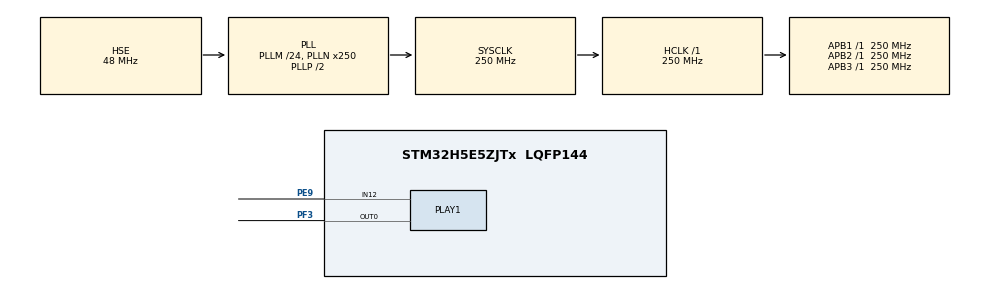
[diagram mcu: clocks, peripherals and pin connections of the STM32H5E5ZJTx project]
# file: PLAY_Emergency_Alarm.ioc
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CORTEX_M33_NS.userName=CORTEX_M33
Mcu.Family=STM32H5
Mcu.Name=STM32H5E5ZJTx
Mcu.Package=LQFP144
NVIC.PLAY1_IRQn=true\:0\:0\:false\:false\:true\:true\:true\:true
NVIC.PriorityGroup=NVIC_PRIORITYGROUP_4
PE9.GPIO_PuPd=GPIO_PULLDOWN
PE9.GPIO_Speed=GPIO_SPEED_FREQ_HIGH
PE9.Mode=PLAY1_IN12
PE9.Signal=PLAY1_IN12
PF3.GPIO_Speed=GPIO_SPEED_FREQ_HIGH
PF3.Mode=PLAY1_OUT0
PF3.Signal=PLAY1_OUT0
PH0-OSC_IN(PH0).Mode=HSE-External-Oscillator
PH0-OSC_IN(PH0).Signal=RCC_OSC_IN
PH1-OSC_OUT(PH1).Mode=HSE-External-Oscillator
PH1-OSC_OUT(PH1).Signal=RCC_OSC_OUT
PLAY1.Channel-PLAY1_IN12=PLAY_CHANNEL_12
PLAY1.InputEdgeDetection12=HAL_PLAY_EDGE_DETECTION_RISING
PLAY1.InputPulseWidth12=0
PLAY1.InputSignal12=HAL_PLAY1_IN_IN12_MUX12
PLAY1.L0ClockEnable=HAL_PLAY_LUT_CLK_GATE_LUT15_OUT_REGISTERED
PLAY1.L0Input0=HAL_PLAY_LUT_INPUT_LUT0_OUT_REGISTERED
PLAY1.L0Input1=HAL_PLAY_LUT_INPUT_SWTRIG0
PLAY1.L0InputType0=OutputRegisteredSignal
PLAY1.L0LUT=0x5555
PLAY1.L10Input0=HAL_PLAY_LUT_INPUT_LUT8_OUT_DIRECT
PLAY1.L10Input1=HAL_PLAY_LUT_INPUT_LUT9_OUT_DIRECT
PLAY1.L10Input2=HAL_PLAY_LUT_INPUT_LUT12_OUT_DIRECT
PLAY1.L10Input3=HAL_PLAY_LUT_INPUT_LUT13_OUT_DIRECT
PLAY1.L10InputType0=OutputDirectSignal
PLAY1.L10InputType1=OutputDirectSignal
PLAY1.L10InputType2=OutputDirectSignal
PLAY1.L10InputType3=OutputDirectSignal
PLAY1.L10LUT=0xFFFE
PLAY1.L11Input0=HAL_PLAY_LUT_INPUT_LUT15_OUT_REGISTERED
PLAY1.L11Input1=HAL_PLAY_LUT_INPUT_LUT10_OUT_DIRECT
PLAY1.L11InputType0=OutputRegisteredSignal
PLAY1.L11InputType1=OutputDirectSignal
PLAY1.L11LUT=0x8888
PLAY1.L12Input0=HAL_PLAY_LUT_INPUT_LUT1_OUT_REGISTERED
PLAY1.L12Input1=HAL_PLAY_LUT_INPUT_LUT2_OUT_REGISTERED
PLAY1.L12Input2=HAL_PLAY_LUT_INPUT_LUT3_OUT_REGISTERED
PLAY1.L12Input3=HAL_PLAY_LUT_INPUT_LUT5_OUT_REGISTERED
PLAY1.L12InputType0=OutputRegisteredSignal
PLAY1.L12InputType1=OutputRegisteredSignal
PLAY1.L12InputType2=OutputRegisteredSignal
PLAY1.L12InputType3=OutputRegisteredSignal
PLAY1.L12LUT=0x0100
PLAY1.L13Input1=HAL_PLAY_LUT_INPUT_LUT1_OUT_REGISTERED
PLAY1.L13Input2=HAL_PLAY_LUT_INPUT_LUT3_OUT_REGISTERED
PLAY1.L13Input3=HAL_PLAY_LUT_INPUT_LUT5_OUT_REGISTERED
PLAY1.L13InputType0=OutputRegisteredSignal
PLAY1.L13InputType1=OutputRegisteredSignal
PLAY1.L13InputType2=OutputRegisteredSignal
PLAY1.L13InputType3=OutputRegisteredSignal
PLAY1.L13LUT=0x0400
PLAY1.L15ClockEnable=HAL_PLAY_LUT_CLK_GATE_FILTER12
PLAY1.L15Input0=HAL_PLAY_LUT_INPUT_LUT15_OUT_REGISTERED
PLAY1.L15InputType0=OutputRegisteredSignal
PLAY1.L15LUT=0x5555
PLAY1.L1ClockEnable=HAL_PLAY_LUT_CLK_GATE_LUT15_OUT_REGISTERED
PLAY1.L1Input0=HAL_PLAY_LUT_INPUT_LUT1_OUT_REGISTERED
PLAY1.L1InputType0=OutputRegisteredSignal
PLAY1.L1InputType1=OutputRegisteredSignal
PLAY1.L1LUT=0x6666
PLAY1.L2ClockEnable=HAL_PLAY_LUT_CLK_GATE_LUT15_OUT_REGISTERED
PLAY1.L2Input0=HAL_PLAY_LUT_INPUT_LUT2_OUT_REGISTERED
PLAY1.L2Input1=HAL_PLAY_LUT_INPUT_LUT1_OUT_REGISTERED
PLAY1.L2InputType0=OutputRegisteredSignal
PLAY1.L2InputType1=OutputRegisteredSignal
PLAY1.L2InputType2=OutputRegisteredSignal
PLAY1.L2LUT=0x6A6A
PLAY1.L3ClockEnable=HAL_PLAY_LUT_CLK_GATE_LUT15_OUT_REGISTERED
PLAY1.L3Input0=HAL_PLAY_LUT_INPUT_LUT3_OUT_REGISTERED
PLAY1.L3Input1=HAL_PLAY_LUT_INPUT_LUT2_OUT_REGISTERED
PLAY1.L3Input2=HAL_PLAY_LUT_INPUT_LUT1_OUT_REGISTERED
PLAY1.L3InputType0=OutputRegisteredSignal
PLAY1.L3InputType1=OutputRegisteredSignal
PLAY1.L3InputType2=OutputRegisteredSignal
PLAY1.L3InputType3=OutputRegisteredSignal
PLAY1.L3LUT=0x6AAA
PLAY1.L4ClockEnable=HAL_PLAY_LUT_CLK_GATE_ON
PLAY1.L4Input0=HAL_PLAY_LUT_INPUT_LUT3_OUT_REGISTERED
PLAY1.L4Input1=HAL_PLAY_LUT_INPUT_LUT2_OUT_REGISTERED
PLAY1.L4Input2=HAL_PLAY_LUT_INPUT_LUT1_OUT_REGISTERED
PLAY1.L4InputType0=OutputRegisteredSignal
PLAY1.L4InputType1=OutputRegisteredSignal
PLAY1.L4InputType2=OutputRegisteredSignal
PLAY1.L4InputType3=OutputRegisteredSignal
PLAY1.L4LUT=0x8000
PLAY1.L5ClockEnable=HAL_PLAY_LUT_CLK_GATE_LUT15_OUT_REGISTERED
PLAY1.L5Input0=HAL_PLAY_LUT_INPUT_LUT5_OUT_REGISTERED
PLAY1.L5Input1=HAL_PLAY_LUT_INPUT_LUT4_OUT_DIRECT
PLAY1.L5InputType0=OutputRegisteredSignal
PLAY1.L5InputType1=OutputDirectSignal
PLAY1.L5LUT=0x6666
PLAY1.L8Input1=HAL_PLAY_LUT_INPUT_LUT2_OUT_REGISTERED
PLAY1.L8Input2=HAL_PLAY_LUT_INPUT_LUT3_OUT_REGISTERED
PLAY1.L8Input3=HAL_PLAY_LUT_INPUT_LUT5_OUT_REGISTERED
PLAY1.L8InputType0=OutputRegisteredSignal
PLAY1.L8InputType1=OutputRegisteredSignal
PLAY1.L8InputType2=OutputRegisteredSignal
PLAY1.L8InputType3=OutputRegisteredSignal
PLAY1.L8LUT=0x1151
PLAY1.L9Input1=HAL_PLAY_LUT_INPUT_LUT1_OUT_REGISTERED
PLAY1.L9Input2=HAL_PLAY_LUT_INPUT_LUT3_OUT_REGISTERED
PLAY1.L9Input3=HAL_PLAY_LUT_INPUT_LUT5_OUT_REGISTERED
PLAY1.L9InputType0=OutputRegisteredSignal
PLAY1.L9InputType1=OutputRegisteredSignal
PLAY1.L9InputType2=OutputRegisteredSignal
PLAY1.L9InputType3=OutputRegisteredSignal
PLAY1.L9LUT=0x0031
PLAY1.LUT0InputUsage0=enable
PLAY1.LUT0InputUsage1=disable
PLAY1.LUT10InputUsage0=enable
PLAY1.LUT10InputUsage1=enable
PLAY1.LUT10InputUsage2=enable
PLAY1.LUT10InputUsage3=enable
PLAY1.LUT11InputUsage0=enable
PLAY1.LUT11InputUsage1=enable
PLAY1.LUT11InputUsage2=disable
PLAY1.LUT11InputUsage3=disable
PLAY1.LUT12InputUsage0=enable
PLAY1.LUT12InputUsage1=enable
PLAY1.LUT12InputUsage2=enable
PLAY1.LUT12InputUsage3=enable
PLAY1.LUT13InputUsage0=enable
PLAY1.LUT13InputUsage1=enable
PLAY1.LUT13InputUsage2=enable
PLAY1.LUT13InputUsage3=enable
PLAY1.LUT15InputUsage0=enable
PLAY1.LUT1InputUsage0=enable
PLAY1.LUT1InputUsage1=enable
PLAY1.LUT2InputUsage0=enable
PLAY1.LUT2InputUsage1=enable
PLAY1.LUT2InputUsage2=enable
PLAY1.LUT3InputUsage0=enable
PLAY1.LUT3InputUsage1=enable
PLAY1.LUT3InputUsage2=enable
PLAY1.LUT3InputUsage3=enable
PLAY1.LUT4InputUsage0=enable
PLAY1.LUT4InputUsage1=enable
PLAY1.LUT4InputUsage2=enable
PLAY1.LUT4InputUsage3=enable
PLAY1.LUT5InputUsage0=enable
PLAY1.LUT5InputUsage1=enable
PLAY1.LUT8InputUsage0=enable
PLAY1.LUT8InputUsage1=enable
PLAY1.LUT8InputUsage2=enable
PLAY1.LUT8InputUsage3=enable
PLAY1.LUT9InputUsage0=enable
PLAY1.LUT9InputUsage1=enable
PLAY1.LUT9InputUsage2=enable
PLAY1.LUT9InputUsage3=enable
PLAY1.OutputSignal0=HAL_PLAY_LUT11_OUT_DIRECT
PLAY1.OutputSignal14=HAL_PLAY_LUT15_OUT_REGISTERED
ProjectManager.HeapSize=0x200
ProjectManager.StackSize=0x400
ProjectManager.TargetToolchain=EWARM V9.20
RCC.ADCFreq_Value=250000000
RCC.AHBFreq_Value=250000000
RCC.APB1Freq_Value=250000000
RCC.APB1TimFreq_Value=250000000
RCC.APB2Freq_Value=250000000
RCC.APB2TimFreq_Value=250000000
RCC.APB3Freq_Value=250000000
RCC.CSI_VALUE=4000000
RCC.CortexFreq_Value=250000000
RCC.EPOD_VALUE=48000000
RCC.HCLKFreq_Value=250000000
RCC.HSE_VALUE=48000000
RCC.HSI48_VALUE=48000000
RCC.HSI_VALUE=64000000
RCC.LSE_VALUE=32768
RCC.LSIRC_VALUE=32000
RCC.PLAY1CLockSelection=RCC_PLAY1CLKSOURCE_LSI
RCC.PLAY1Prescaler=RCC_PLAY1_CLK_DIV_4096
RCC.PLL2M=2
RCC.PLL2N=8
RCC.PLL2Source=RCC_PLL2_SOURCE_HSI
RCC.PLLM=24
RCC.PLLN=250
RCC.PLLSourceVirtual=RCC_PLL1_SOURCE_HSE
RCC.SYSCLKFreq_VALUE=250000000
RCC.SYSCLKSource=RCC_SYSCLKSOURCE_PLLCLK
RCC.USBFreq_Value=258000000
RCC.VCOOutputFreq_Value=500000000
VP_CORTEX_M33_NS_VS_Hclk.Mode=Hclk_Mode
VP_ICACHE_VS_ICACHE.Mode=DefaultMode
VP_PLAY1_VS_PLA.Mode=PLAY_Activate
VP_PWR_VS_LPOM.Mode=PowerOptimisation
VP_PWR_VS_SECSignals.Mode=Security/Privilege
board=custom

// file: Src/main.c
/* USER CODE BEGIN Header */
/**
  ******************************************************************************
  * @file           : main.c
  * @brief          : Main program body
  ******************************************************************************
  * @attention
  *
  * Copyright (c) 2025 STMicroelectronics.
  * All rights reserved.
  *
  * This software is licensed under terms that can be found in the LICENSE file
  * in the root directory of this software component.
  * If no LICENSE file comes with this software, it is provided AS-IS.
  *
  ******************************************************************************
  */
/* USER CODE END Header */
#include "main.h"

#define CONFIGURED_INPUT_NBR   1U
#define CONFIGURED_LUT_NBR     13U
#define CONFIGURED_OUTPUT_NBR  2U

HAL_PLAY_HandleTypeDef hplay1;

/* USER CODE BEGIN PV */
EXTI_HandleTypeDef hexti;
/* USER CODE END PV */

void SystemClock_Config(void);
static void MX_GPIO_Init(void);
static void MX_ICACHE_Init(void);
static void MX_PLAY1_Init(void);

int main(void)
{

  /* USER CODE BEGIN 1 */
  HAL_PLAY_EdgeTriggerConfTypeDef edge_trigger_config;

  /* USER CODE END 1 */

  /* MCU Configuration--------------------------------------------------------*/

  /* Reset of all peripherals, Initializes the Flash interface and the Systick. */
  HAL_Init();

  /* USER CODE BEGIN Init */
  HAL_PWR_EnableBkUpAccess();
  /* USER CODE END Init */

  /* Configure the system clock */
  SystemClock_Config();

  /* Initialize all configured peripherals */
  MX_GPIO_Init();
  MX_ICACHE_Init();
  MX_PLAY1_Init();
  /* USER CODE BEGIN 2 */
  BSP_LED_Init(LED_RED);
  BSP_LED_Init(LED_BLUE);

  /* In this example, edge triggers are not used */
  edge_trigger_config.lut_out_falling_mask = 0U;
  edge_trigger_config.lut_out_rising_mask = 0U;

  /* Start PLAY module */
  if (HAL_PLAY_Start(&hplay1, &edge_trigger_config) != HAL_OK)
  {
    Error_Handler();
  }

  /* USER CODE END 2 */

  /* Infinite loop */
  /* USER CODE BEGIN WHILE */
  while (1)
  {
    /* The system enters STOP mode to demonstrate that the alarm signal is fully handled by the PLAY hardware */

    HAL_SuspendTick();

    /* Clear all related wakeup flags*/
    __HAL_PWR_CLEAR_FLAG(PWR_FLAG_STOPF);

    /** Enter STOP Mode with WaitForevent parameter, a interrupt enabled in NVIC would wake the system up
      * During STOP mode, the PLAY LUT output flags are not functional.
      * To wakeup the system, this example configures the PLAY EXTI output so that the falling edge of LUT 15
      * will trigger the EXTI, waking up the system.
      */
    HAL_PWR_EnterSTOPMode(PWR_MAINREGULATOR_ON, PWR_STOPENTRY_WFE);

    /**
      * The user can change the PLAY1_IN12 (PE9) input signal to trigger the alarm signal.
      * As the PLAY peripheral handles the alarm signal, the application does not need to do anything in this step.
      * When the user changes the input signal a second time, the PLAY peripheral will stop the alarm signal.
      * The alarm stop will trigger an EXTI interrupt, which will wake the system.
      * The application will then turn on the LED to indicate that the alarm has been stopped, wait for one second,
      * and go back again in STOP mode.
      */

    /* Reach this point when the MCU wakes up */
    HAL_ResumeTick();

    /* The PLAY interrupt wakes the device up */
    SystemClock_Config();

    /* The alarm was stopped: rising edge on LUT 15 registered output. Turn on the LED */
    BSP_LED_On(LED_BLUE);

    /* Wait for one second so the LED status can be noticed.*/
    HAL_Delay(1000);
    BSP_LED_Off(LED_BLUE);
    /* USER CODE END WHILE */

  }
}

void SystemClock_Config(void)
{
  RCC_OscInitTypeDef RCC_OscInitStruct = {0};
  RCC_ClkInitTypeDef RCC_ClkInitStruct = {0};

  /** Configure the main internal regulator output voltage
  */
  __HAL_PWR_VOLTAGESCALING_CONFIG(PWR_REGULATOR_VOLTAGE_SCALE0);

  while(!__HAL_PWR_GET_FLAG(PWR_FLAG_VOSRDY)) {}

  /** Initializes the RCC Oscillators according to the specified parameters
  * in the RCC_OscInitTypeDef structure.
  */
  RCC_OscInitStruct.OscillatorType = RCC_OSCILLATORTYPE_LSI|RCC_OSCILLATORTYPE_HSE;
  RCC_OscInitStruct.HSEState = RCC_HSE_ON;
  RCC_OscInitStruct.LSIState = RCC_LSI_ON;
  RCC_OscInitStruct.PLL.PLLState = RCC_PLL_ON;
  RCC_OscInitStruct.PLL.PLLSource = RCC_PLL1_SOURCE_HSE;
  RCC_OscInitStruct.PLL.PLLM = 24;
  RCC_OscInitStruct.PLL.PLLN = 250;
  RCC_OscInitStruct.PLL.PLLP = 2;
  RCC_OscInitStruct.PLL.PLLQ = 2;
  RCC_OscInitStruct.PLL.PLLR = 2;
  RCC_OscInitStruct.PLL.PLLRGE = RCC_PLL1_VCIRANGE_1;
  RCC_OscInitStruct.PLL.PLLVCOSEL = RCC_PLL1_VCORANGE_WIDE;
  RCC_OscInitStruct.PLL.PLLFRACN = 0;
  if (HAL_RCC_OscConfig(&RCC_OscInitStruct) != HAL_OK)
  {
    Error_Handler();
  }

  /** Initializes the CPU, AHB and APB buses clocks
  */
  RCC_ClkInitStruct.ClockType = RCC_CLOCKTYPE_HCLK|RCC_CLOCKTYPE_SYSCLK
                              |RCC_CLOCKTYPE_PCLK1|RCC_CLOCKTYPE_PCLK2
                              |RCC_CLOCKTYPE_PCLK3;
  RCC_ClkInitStruct.SYSCLKSource = RCC_SYSCLKSOURCE_PLLCLK;
  RCC_ClkInitStruct.AHBCLKDivider = RCC_SYSCLK_DIV1;
  RCC_ClkInitStruct.APB1CLKDivider = RCC_HCLK_DIV1;
  RCC_ClkInitStruct.APB2CLKDivider = RCC_HCLK_DIV1;
  RCC_ClkInitStruct.APB3CLKDivider = RCC_HCLK_DIV1;

  if (HAL_RCC_ClockConfig(&RCC_ClkInitStruct, FLASH_LATENCY_5) != HAL_OK)
  {
    Error_Handler();
  }

  /** Configure the programming delay
  */
  __HAL_FLASH_SET_PROGRAM_DELAY(FLASH_PROGRAMMING_DELAY_2);
}

static void MX_ICACHE_Init(void)
{

  /** Enable instruction cache (default 2-ways set associative cache)
  */
  if (HAL_ICACHE_Enable() != HAL_OK)
  {
    Error_Handler();
  }

}

static void MX_PLAY1_Init(void)
{

  HAL_PLAY_IN_ConfTypeDef configINPUTs[CONFIGURED_INPUT_NBR];
  HAL_PLAY_LUT_ConfTypeDef configLUTs[CONFIGURED_LUT_NBR];
  HAL_PLAY_OUT_ConfTypeDef configOUTPUTs[CONFIGURED_OUTPUT_NBR];

  hplay1.instance = PLAY1;

  if (HAL_PLAY_Init(&hplay1) != HAL_OK)
  {
    Error_Handler();
  }

  /** Configure Input 12
  */
  configINPUTs[0].min_pulse_width = 0;
  configINPUTs[0].mode = HAL_PLAY_EDGE_DETECTION_RISING;
  configINPUTs[0].source = HAL_PLAY1_IN_IN12_MUX12;
  if (HAL_PLAY_INPUT_SetConfig(&hplay1, configINPUTs, CONFIGURED_INPUT_NBR) != HAL_OK)
  {
    Error_Handler();
  }

  /** Configure the Logic Element 0
  */
  configLUTs[0].lut = HAL_PLAY_LUT0;
  configLUTs[0].truth_table = 0x5555;
  configLUTs[0].input_source[HAL_PLAY_LUT_INPUT0] = HAL_PLAY_LUT_INPUT_LUT0_OUT_REGISTERED;
  configLUTs[0].input_source[HAL_PLAY_LUT_INPUT1] = HAL_PLAY_LUT_INPUT_SWTRIG0;
  configLUTs[0].input_source[HAL_PLAY_LUT_INPUT2] = HAL_PLAY_LUT_INPUT_DEFAULT;
  configLUTs[0].input_source[HAL_PLAY_LUT_INPUT3] = HAL_PLAY_LUT_INPUT_DEFAULT;
  configLUTs[0].clk_gate_source = HAL_PLAY_LUT_CLK_GATE_LUT15_OUT_REGISTERED;

  /** Configure the Logic Element 1
  */
  configLUTs[1].lut = HAL_PLAY_LUT1;
  configLUTs[1].truth_table = 0x6666;
  configLUTs[1].input_source[HAL_PLAY_LUT_INPUT0] = HAL_PLAY_LUT_INPUT_LUT1_OUT_REGISTERED;
  configLUTs[1].input_source[HAL_PLAY_LUT_INPUT1] = HAL_PLAY_LUT_INPUT_LUT0_OUT_REGISTERED;
  configLUTs[1].input_source[HAL_PLAY_LUT_INPUT2] = HAL_PLAY_LUT_INPUT_DEFAULT;
  configLUTs[1].input_source[HAL_PLAY_LUT_INPUT3] = HAL_PLAY_LUT_INPUT_DEFAULT;
  configLUTs[1].clk_gate_source = HAL_PLAY_LUT_CLK_GATE_LUT15_OUT_REGISTERED;

  /** Configure the Logic Element 2
  */
  configLUTs[2].lut = HAL_PLAY_LUT2;
  configLUTs[2].truth_table = 0x6A6A;
  configLUTs[2].input_source[HAL_PLAY_LUT_INPUT0] = HAL_PLAY_LUT_INPUT_LUT2_OUT_REGISTERED;
  configLUTs[2].input_source[HAL_PLAY_LUT_INPUT1] = HAL_PLAY_LUT_INPUT_LUT1_OUT_REGISTERED;
  configLUTs[2].input_source[HAL_PLAY_LUT_INPUT2] = HAL_PLAY_LUT_INPUT_LUT0_OUT_REGISTERED;
  configLUTs[2].input_source[HAL_PLAY_LUT_INPUT3] = HAL_PLAY_LUT_INPUT_DEFAULT;
  configLUTs[2].clk_gate_source = HAL_PLAY_LUT_CLK_GATE_LUT15_OUT_REGISTERED;

  /** Configure the Logic Element 3
  */
  configLUTs[3].lut = HAL_PLAY_LUT3;
  configLUTs[3].truth_table = 0x6AAA;
  configLUTs[3].input_source[HAL_PLAY_LUT_INPUT0] = HAL_PLAY_LUT_INPUT_LUT3_OUT_REGISTERED;
  configLUTs[3].input_source[HAL_PLAY_LUT_INPUT1] = HAL_PLAY_LUT_INPUT_LUT2_OUT_REGISTERED;
  configLUTs[3].input_source[HAL_PLAY_LUT_INPUT2] = HAL_PLAY_LUT_INPUT_LUT1_OUT_REGISTERED;
  configLUTs[3].input_source[HAL_PLAY_LUT_INPUT3] = HAL_PLAY_LUT_INPUT_LUT0_OUT_REGISTERED;
  configLUTs[3].clk_gate_source = HAL_PLAY_LUT_CLK_GATE_LUT15_OUT_REGISTERED;

  /** Configure the Logic Element 4
  */
  configLUTs[4].lut = HAL_PLAY_LUT4;
  configLUTs[4].truth_table = 0x8000;
  configLUTs[4].input_source[HAL_PLAY_LUT_INPUT0] = HAL_PLAY_LUT_INPUT_LUT3_OUT_REGISTERED;
  configLUTs[4].input_source[HAL_PLAY_LUT_INPUT1] = HAL_PLAY_LUT_INPUT_LUT2_OUT_REGISTERED;
  configLUTs[4].input_source[HAL_PLAY_LUT_INPUT2] = HAL_PLAY_LUT_INPUT_LUT1_OUT_REGISTERED;
  configLUTs[4].input_source[HAL_PLAY_LUT_INPUT3] = HAL_PLAY_LUT_INPUT_LUT0_OUT_REGISTERED;
  configLUTs[4].clk_gate_source = HAL_PLAY_LUT_CLK_GATE_ON;

  /** Configure the Logic Element 5
  */
  configLUTs[5].lut = HAL_PLAY_LUT5;
  configLUTs[5].truth_table = 0x6666;
  configLUTs[5].input_source[HAL_PLAY_LUT_INPUT0] = HAL_PLAY_LUT_INPUT_LUT5_OUT_REGISTERED;
  configLUTs[5].input_source[HAL_PLAY_LUT_INPUT1] = HAL_PLAY_LUT_INPUT_LUT4_OUT_DIRECT;
  configLUTs[5].input_source[HAL_PLAY_LUT_INPUT2] = HAL_PLAY_LUT_INPUT_DEFAULT;
  configLUTs[5].input_source[HAL_PLAY_LUT_INPUT3] = HAL_PLAY_LUT_INPUT_DEFAULT;
  configLUTs[5].clk_gate_source = HAL_PLAY_LUT_CLK_GATE_LUT15_OUT_REGISTERED;

  /** Configure the Logic Element 8
  */
  configLUTs[6].lut = HAL_PLAY_LUT8;
  configLUTs[6].truth_table = 0x1151;
  configLUTs[6].input_source[HAL_PLAY_LUT_INPUT0] = HAL_PLAY_LUT_INPUT_LUT0_OUT_REGISTERED;
  configLUTs[6].input_source[HAL_PLAY_LUT_INPUT1] = HAL_PLAY_LUT_INPUT_LUT2_OUT_REGISTERED;
  configLUTs[6].input_source[HAL_PLAY_LUT_INPUT2] = HAL_PLAY_LUT_INPUT_LUT3_OUT_REGISTERED;
  configLUTs[6].input_source[HAL_PLAY_LUT_INPUT3] = HAL_PLAY_LUT_INPUT_LUT5_OUT_REGISTERED;
  configLUTs[6].clk_gate_source = HAL_PLAY_LUT_CLK_GATE_OFF;

  /** Configure the Logic Element 9
  */
  configLUTs[7].lut = HAL_PLAY_LUT9;
  configLUTs[7].truth_table = 0x0031;
  configLUTs[7].input_source[HAL_PLAY_LUT_INPUT0] = HAL_PLAY_LUT_INPUT_LUT0_OUT_REGISTERED;
  configLUTs[7].input_source[HAL_PLAY_LUT_INPUT1] = HAL_PLAY_LUT_INPUT_LUT1_OUT_REGISTERED;
  configLUTs[7].input_source[HAL_PLAY_LUT_INPUT2] = HAL_PLAY_LUT_INPUT_LUT3_OUT_REGISTERED;
  configLUTs[7].input_source[HAL_PLAY_LUT_INPUT3] = HAL_PLAY_LUT_INPUT_LUT5_OUT_REGISTERED;
  configLUTs[7].clk_gate_source = HAL_PLAY_LUT_CLK_GATE_OFF;

  /** Configure the Logic Element 10
  */
  configLUTs[8].lut = HAL_PLAY_LUT10;
  configLUTs[8].truth_table = 0xFFFE;
  configLUTs[8].input_source[HAL_PLAY_LUT_INPUT0] = HAL_PLAY_LUT_INPUT_LUT8_OUT_DIRECT;
  configLUTs[8].input_source[HAL_PLAY_LUT_INPUT1] = HAL_PLAY_LUT_INPUT_LUT9_OUT_DIRECT;
  configLUTs[8].input_source[HAL_PLAY_LUT_INPUT2] = HAL_PLAY_LUT_INPUT_LUT12_OUT_DIRECT;
  configLUTs[8].input_source[HAL_PLAY_LUT_INPUT3] = HAL_PLAY_LUT_INPUT_LUT13_OUT_DIRECT;
  configLUTs[8].clk_gate_source = HAL_PLAY_LUT_CLK_GATE_OFF;

  /** Configure the Logic Element 11
  */
  configLUTs[9].lut = HAL_PLAY_LUT11;
  configLUTs[9].truth_table = 0x8888;
  configLUTs[9].input_source[HAL_PLAY_LUT_INPUT0] = HAL_PLAY_LUT_INPUT_LUT15_OUT_REGISTERED;
  configLUTs[9].input_source[HAL_PLAY_LUT_INPUT1] = HAL_PLAY_LUT_INPUT_LUT10_OUT_DIRECT;
  configLUTs[9].input_source[HAL_PLAY_LUT_INPUT2] = HAL_PLAY_LUT_INPUT_DEFAULT;
  configLUTs[9].input_source[HAL_PLAY_LUT_INPUT3] = HAL_PLAY_LUT_INPUT_DEFAULT;
  configLUTs[9].clk_gate_source = HAL_PLAY_LUT_CLK_GATE_OFF;

  /** Configure the Logic Element 12
  */
  configLUTs[10].lut = HAL_PLAY_LUT12;
  configLUTs[10].truth_table = 0x0100;
  configLUTs[10].input_source[HAL_PLAY_LUT_INPUT0] = HAL_PLAY_LUT_INPUT_LUT1_OUT_REGISTERED;
  configLUTs[10].input_source[HAL_PLAY_LUT_INPUT1] = HAL_PLAY_LUT_INPUT_LUT2_OUT_REGISTERED;
  configLUTs[10].input_source[HAL_PLAY_LUT_INPUT2] = HAL_PLAY_LUT_INPUT_LUT3_OUT_REGISTERED;
  configLUTs[10].input_source[HAL_PLAY_LUT_INPUT3] = HAL_PLAY_LUT_INPUT_LUT5_OUT_REGISTERED;
  configLUTs[10].clk_gate_source = HAL_PLAY_LUT_CLK_GATE_OFF;

  /** Configure the Logic Element 13
  */
  configLUTs[11].lut = HAL_PLAY_LUT13;
  configLUTs[11].truth_table = 0x0400;
  configLUTs[11].input_source[HAL_PLAY_LUT_INPUT0] = HAL_PLAY_LUT_INPUT_LUT0_OUT_REGISTERED;
  configLUTs[11].input_source[HAL_PLAY_LUT_INPUT1] = HAL_PLAY_LUT_INPUT_LUT1_OUT_REGISTERED;
  configLUTs[11].input_source[HAL_PLAY_LUT_INPUT2] = HAL_PLAY_LUT_INPUT_LUT3_OUT_REGISTERED;
  configLUTs[11].input_source[HAL_PLAY_LUT_INPUT3] = HAL_PLAY_LUT_INPUT_LUT5_OUT_REGISTERED;
  configLUTs[11].clk_gate_source = HAL_PLAY_LUT_CLK_GATE_OFF;

  /** Configure the Logic Element 15
  */
  configLUTs[12].lut = HAL_PLAY_LUT15;
  configLUTs[12].truth_table = 0x5555;
  configLUTs[12].input_source[HAL_PLAY_LUT_INPUT0] = HAL_PLAY_LUT_INPUT_LUT15_OUT_REGISTERED;
  configLUTs[12].input_source[HAL_PLAY_LUT_INPUT1] = HAL_PLAY_LUT_INPUT_DEFAULT;
  configLUTs[12].input_source[HAL_PLAY_LUT_INPUT2] = HAL_PLAY_LUT_INPUT_DEFAULT;
  configLUTs[12].input_source[HAL_PLAY_LUT_INPUT3] = HAL_PLAY_LUT_INPUT_DEFAULT;
  configLUTs[12].clk_gate_source = HAL_PLAY_LUT_CLK_GATE_FILTER12;
  if (HAL_PLAY_LUT_SetConfig(&hplay1, configLUTs, CONFIGURED_LUT_NBR) != HAL_OK)
  {
    Error_Handler();
  }

  /** Configure Output 0
  */
  configOUTPUTs[0].output_mux = HAL_PLAY_OUT0;
  configOUTPUTs[0].lut_output = HAL_PLAY_LUT11_OUT_DIRECT;

  /** Configure Output 14
  */
  configOUTPUTs[1].output_mux = HAL_PLAY_OUT14;
  configOUTPUTs[1].lut_output = HAL_PLAY_LUT15_OUT_REGISTERED;
  if (HAL_PLAY_OUTPUT_SetConfig(&hplay1, configOUTPUTs, CONFIGURED_OUTPUT_NBR) != HAL_OK)
  {
    Error_Handler();
  }

  /** PLAY Privileged access configuration
  */
  HAL_PLAY_SetPrivAttr(&hplay1, HAL_PLAY_PRIV_ITEM_ALL, HAL_PLAY_NPRIV);
  /* USER CODE BEGIN PLAY1_Init 2 */
  EXTI_ConfigTypeDef exti_config;

  /* EXTI line 64 is connected to PLAY1_OUT14 */
  exti_config.Line = EXTI_LINE_64;
  exti_config.Mode = EXTI_MODE_EVENT;
  exti_config.Trigger = EXTI_TRIGGER_FALLING;

  if (HAL_EXTI_SetConfigLine(&hexti, &exti_config) != HAL_OK)
  {
    Error_Handler();
  }
  /* USER CODE END PLAY1_Init 2 */

}

static void MX_GPIO_Init(void)
{

  /* GPIO Ports Clock Enable */
  __HAL_RCC_GPIOH_CLK_ENABLE();

}

void Error_Handler(void)
{
  /* USER CODE BEGIN Error_Handler_Debug */
  /* User can add his own implementation to report the HAL error return state */
  __disable_irq();
  while (1)
  {
    BSP_LED_Toggle(LED_RED);
    HAL_Delay(1000);
  }
  /* USER CODE END Error_Handler_Debug */
}
